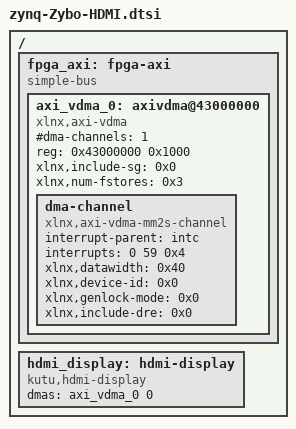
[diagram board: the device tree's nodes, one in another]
/ {
	fpga_axi: fpga-axi {
		compatible = "simple-bus";
		#address-cells = <0x1>;
		#size-cells = <0x1>;
		ranges;

		axi_vdma_0: axivdma@43000000 {
			compatible = "xlnx,axi-vdma";
			#address-cells = <1>;
			#size-cells = <1>;
			#dma-cells = <1>;
			#dma-channels = <1>;
			reg = <0x43000000 0x1000>;
			xlnx,include-sg = <0x0>;
			xlnx,num-fstores = <0x3>;
			dma-channel {
				compatible = "xlnx,axi-vdma-mm2s-channel";
				interrupt-parent = <&intc>;
				interrupts = <0 59 0x4>;
				xlnx,datawidth = <0x40>;
				xlnx,device-id = <0x0>;
				xlnx,genlock-mode = <0x0>;
				xlnx,include-dre = <0x0>;
			};
		};
   };

	hdmi_display: hdmi-display {
		compatible = "kutu,hdmi-display";
		dmas = <&axi_vdma_0 0>;
		dma-names = "video";
	};

};
